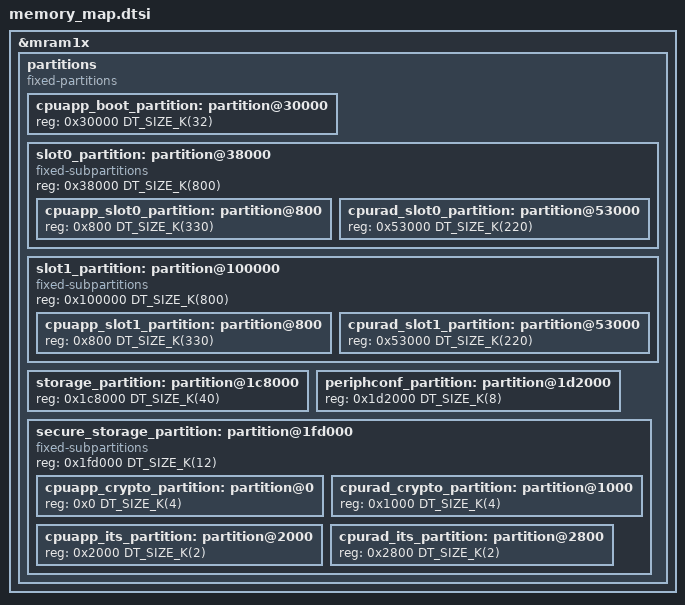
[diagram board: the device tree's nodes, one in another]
/*
 * Copyright (c) 2025-2026 Nordic Semiconductor ASA
 *
 * SPDX-License-Identifier: LicenseRef-Nordic-5-Clause
 */

&mram1x {
	/delete-node/ partitions;

	/* Redefine the "partitions" DTS node. */
	partitions {
		compatible = "fixed-partitions";
		#address-cells = <1>;
		#size-cells = <1>;
		ranges;

		/* Partitions belonging to the MRAM_10 memory block.
		 * The start of the MRAM_10 memory is reserved for internal IronSide SE firmware.
		 */

		cpuapp_boot_partition: partition@30000 {
			reg = <0x30000 DT_SIZE_K(32)>;
		};

		/* When using merged slots, the definition of MCUboot slots is common for all
		 * images and points to the "merged" partition.
		 */
		slot0_partition: partition@38000 {
			compatible = "fixed-subpartitions";
			reg = <0x38000 DT_SIZE_K(800)>;
			ranges = <0x0 0x38000 DT_SIZE_K(800)>;
			#address-cells = <1>;
			#size-cells = <1>;

			cpuapp_slot0_partition: partition@800 {
				reg = <0x800 DT_SIZE_K(330)>;
			};

			cpurad_slot0_partition: partition@53000 {
				reg = <0x53000 DT_SIZE_K(220)>;
			};

			/* Leave free space at the end of the slot0_partition that can be used to
			 * increase the existing application or radio partition. Optimizing the size
			 * of the application and radio partition results in a smaller DFU package
			 * and faster DFU transfer.
			 */
		};

		/* Partitions belonging to the MRAM_11 memory block. */

		slot1_partition: partition@100000 {
			compatible = "fixed-subpartitions";
			reg = <0x100000 DT_SIZE_K(800)>;
			ranges = <0x0 0x100000 DT_SIZE_K(800)>;
			#address-cells = <1>;
			#size-cells = <1>;

			cpuapp_slot1_partition: partition@800 {
				reg = <0x800 DT_SIZE_K(330)>;
			};

			cpurad_slot1_partition: partition@53000 {
				reg = <0x53000 DT_SIZE_K(220)>;
			};

			/* Leave free space at the end of the slot1_partition that can be used to
			 * increase the existing application or radio partition. Optimizing the size
			 * of the application and radio partition results in a smaller DFU package
			 * and faster DFU transfer.
			 */
		};

		storage_partition: partition@1c8000 {
			reg = <0x1c8000 DT_SIZE_K(40)>;
		};

		periphconf_partition: partition@1d2000 {
			reg = <0x1d2000 DT_SIZE_K(8)>;
		};

		/* A gap of 164 KB (0x29000) has been left here for future partitions. */

		/* 0x1fd000 was chosen for secure_storage_partition such that
		 * there is no more space after secure_storage_partition.
		 */
		secure_storage_partition: partition@1fd000 {
			compatible = "fixed-subpartitions";
			reg = <0x1fd000 DT_SIZE_K(12)>;
			ranges = <0x0 0x1fd000 DT_SIZE_K(12)>;
			#address-cells = <1>;
			#size-cells = <1>;

			cpuapp_crypto_partition: partition@0 {
				reg = <0x0 DT_SIZE_K(4)>;
			};

			cpurad_crypto_partition: partition@1000 {
				reg = <0x1000 DT_SIZE_K(4)>;
			};

			cpuapp_its_partition: partition@2000 {
				reg = <0x2000 DT_SIZE_K(2)>;
			};

			cpurad_its_partition: partition@2800 {
				reg = <0x2800 DT_SIZE_K(2)>;
			};
		};
	};
};
